# RSL15 register map
Vendor: ONSemiconductor; Series: RSL15 Series; File version: 1.0
CPU: CM33 r0p4, little endian, MPU, FPU, 3 interrupt priority bits
Registers are 32-bit, read-write, reset 0x0 unless marked. A register's access mark holds for its fields unless they carry their own. Offsets are from the block's base; [hi:lo] are bit positions; {n}, {i} and the like mark numbered series.

## LIN — LIN Interface
Base 0x40002000
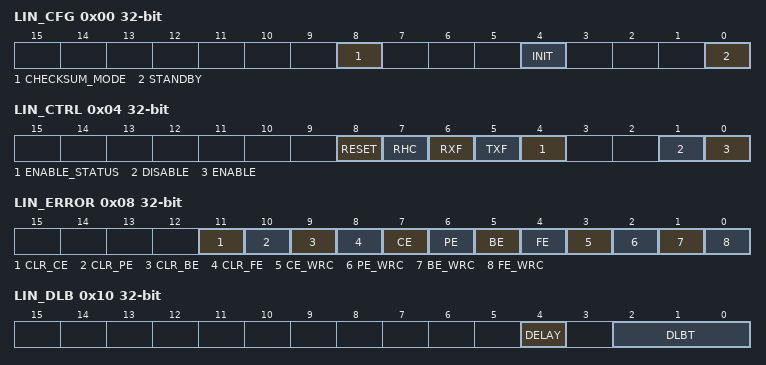
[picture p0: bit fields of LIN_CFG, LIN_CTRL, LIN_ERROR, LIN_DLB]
0x00 LIN_CFG — LIN Configuration Register
  [8] CHECKSUM_MODE — Select checksum mode
    0=ID_IN_CHECKSUM (Enhance check sum, include ID); 1=ONLY_DATA_IN_CHECKSUM (Classic check sum, only data byte)
  [4] INIT — Start C617 initialization
    0=NOT_INIT_C617; 1=INIT_C617
  [0] STANDBY ro — C617 state
    0=STANDBY_STATE; 1=NORMAL_MODE
0x04 LIN_CTRL (reset mask 0xF0) — LIN Control Register
  [8] RESET wo — Reset the LIN module to default configuration
    1=LIN_RESET (Reset the LIN module)
  [7] RHC ro — This bit is set, when frame header is successfully received (synchronization passed and frame identifier received). Bit is cleared during transition to RX_ID state. Setting of bit to high by controller has higher priority than bit clear by CM33 (frame identifier received). Bit is cleared on MCU read. Bit is cleared during transition to RX_ID state. Setting of bit to high by controller has higher priority than bit clear by CM33
    0=NO_LIN_FH_RX (No frame header received); 1=LIN_FH_RX (Frame header received)
  [6] RXF ro — This bit is set when LIN controller successfully receives all data bytes and checksum is correct. Bit is cleared during transition to RX_ID state. Setting of bit to high by controller has higher priority than bit clear by CM33.
    0=LIN_RX_ONGOING (Recevied process on-going); 1=LIN_RX_DONE (Received process done)
  [5] TXF ro — This bit is set when controller starts to transmit. Bit is cleared when all bytes are transmitted or bit error occurs or break/sync is detected or during transition to RX_ID state.
    0=LIN_TX_DONE (Transmit process done); 1=LIN_TX_ONGOING (Transmit process on-going)
  [4] ENABLE_STATUS ro — LIN enable status
    0=LIN_STATUS_DISABLE (LIN inactives); 1=LIN_STATUS_ENABLE (LIN actives)
  [1] DISABLE wo — Disable the LIN
    1=LIN_DISABLE (LIN disables)
  [0] ENABLE wo — Enable the LIN
    1=LIN_ENABLE (LIN enables)
0x08 LIN_ERROR (reset mask 0xFF)
  [11] CLR_CE wo — Clear Checksum error flag
    1=CLR_CE (Clear checksum error flag)
  [10] CLR_PE wo — Clear Parity error flag
    1=CLR_PE (Clear parity error flag)
  [9] CLR_BE wo — Clear Bit error flag
    1=CLR_BE (Clear bit error flag)
  [8] CLR_FE wo — Clear Frame error flag
    1=CLR_FE (Clear frame error flag)
  [7] CE ro — Checksum error: this bit is set to high when all data bytes are received but value of calculated checksum does not equal the value of 255.
    0=NO_CHECKSUM_ERROR; 1=CHECKSUM_ERROR (Checksum error occurs)
  [6] PE ro — Parity error: this bit is set when parity of received identifier is different from calculated parity.
    0=NO_PARITY_ERROR; 1=PARITY_ERROR (Parity error occurs)
  [5] BE ro — Bit error: this bit is set when transmitted data is different from read back data. This bit is cleared on MCU read.
    0=NO_BIT_ERROR; 1=BIT_ERROR (Bit error occurs)
  [4] FE ro — Framing error: this bit is set when received stop bit is 0 in sync field, identifier or data byte.
    0=NO_FRAME_ERROR; 1=FRAME_ERROR (Frame error occurs)
  [3] CE_WRC ro — Checksum error: this bit is set to high when all data bytes are received but value of calculated checksum does not equal the value of 255. This bit is cleared on MCU read.
    0=NO_CHECKSUM_ERROR_WRC; 1=CHECKSUM_ERROR_WRC (Checksum error occurs)
  [2] PE_WRC ro — Parity error: this bit is set when parity of received identifier is different from calculated parity. This bit is cleared on MCU read.
    0=NO_PARITY_ERROR_WRC; 1=PARITY_ERROR_WRC (Parity error occurs)
  [1] BE_WRC ro — Bit error: this bit is set when transmitted data is different from read back data. This bit is cleared on MCU read.
    0=NO_BIT_ERROR_WRC; 1=BIT_ERROR_WRC (Bit error occurs)
  [0] FE_WRC ro — Framing error: this bit is set when received stop bit is 0 in sync field, identifier or data byte. This bit is cleared on MCU read.
    0=NO_FRAME_ERROR_WRC; 1=FRAME_ERROR_WRC (Frame error occurs)
0x0C LIN_PID ro — LIN Protected Identifier Register
  [7:0] PID — LIN Protected Identifier register
0x10 LIN_DLB — LIN number of bytes to transmit
  [4] DELAY — Complete the PID stop bit before sending the first byte
    0=NO_DELAY (No delay added); 1=ADD_DELAY (Finished the Stop bit before sending the byte.)
  [2:0] DLBT — Number of data bytes to transmit.
    0=TX_1_BYTE (1 byte will be transmitted); {v}=TX_{v+1}_BYTES ({v+1} bytes will be transmitted) (v=1..7)
0x14 LIN_DLBR — LIN number of bytes to receive
  [2:0] DLBR — Number of data bytes to receive.
    0=RX_1_BYTE (1 byte will be received); {v}=RX_{v+1}_BYTES ({v+1} bytes will be received) (v=1..7)
{0x18+4i} LIN_DATA[{i}] (i=0..7) — LIN Data Byte Register (Byte access)
  [7:0] DATA — LIN Data byte received or to transmit
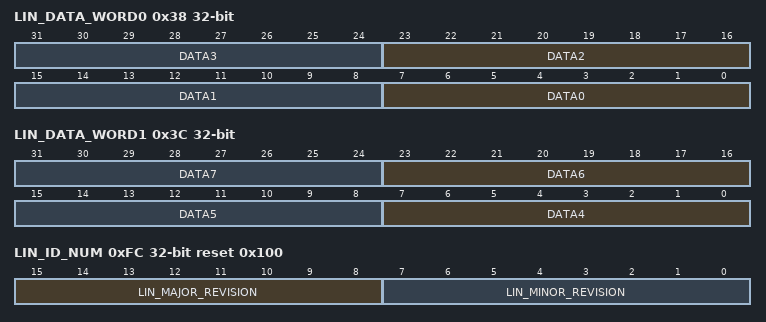
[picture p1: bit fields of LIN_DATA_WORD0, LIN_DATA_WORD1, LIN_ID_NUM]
0x38 LIN_DATA_WORD0 — LIN Data Byte Register (Word access)
  [8n+7:8n] DATA{n} (n=0..3) — LIN Data[{n}] byte received or to transmit
0x3C LIN_DATA_WORD1 — LIN Data Byte Register (Word access)
  [8n-25:8n-32] DATA{n} (n=4..7) — LIN Data[{n}] byte received or to transmit
0x40 LIN_CHECKSUM ro
  [7:0] CHECKSUM
0xF4 LIN_SYNCH ro — LIN
  [13:0] TSYNC — Duration of TSYNC
0xFC LIN_ID_NUM ro reset 0x100 — LIN ID Number
  [15:8] LIN_MAJOR_REVISION — LIN Major Revision number
    1=LIN_MAJOR_REVISION (LIN revision 1.0)
  [7:0] LIN_MINOR_REVISION — LIN Minor Revision number
    0=LIN_MINOR_REVISION (LIN revision 1.0)
